AUTOSAR XML (schema 4-2-2)
package /MCU_FlatView/SwComponentTypes
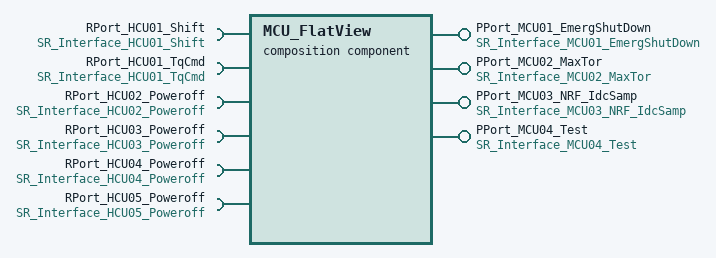
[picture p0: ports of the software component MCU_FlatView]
  composition sw component type MCU_FlatView
    provide port PPort_MCU01_EmergShutDown: provided-interface=SR_Interface_MCU01_EmergShutDown
    provide port PPort_MCU02_MaxTor: provided-interface=SR_Interface_MCU02_MaxTor
    provide port PPort_MCU03_NRF_IdcSamp: provided-interface=SR_Interface_MCU03_NRF_IdcSamp
    4 x require port:
      RPort_HCU01_Shift: nonqueued-receiver-com-spec{data-element=HCU01_Shift, alive-timeout=0.3}, required-interface=SR_Interface_HCU01_Shift
      RPort_HCU01_TqCmd: nonqueued-receiver-com-spec{data-element=HCU01_Tq_Cmd, alive-timeout=0.3}, required-interface=SR_Interface_HCU01_TqCmd
      RPort_HCU02_Poweroff: nonqueued-receiver-com-spec{data-element=HCU02_Poweroff, alive-timeout=0.3}, required-interface=SR_Interface_HCU02_Poweroff
      RPort_HCU03_Poweroff: nonqueued-receiver-com-spec{data-element=HCU03_Poweroff, alive-timeout=0.3}, required-interface=SR_Interface_HCU03_Poweroff
    provide port PPort_MCU04_Test: provided-interface=SR_Interface_MCU04_Test
    require port RPort_HCU04_Poweroff: nonqueued-receiver-com-spec{data-element=HCU04_Poweroff, alive-timeout=0.3}, required-interface=SR_Interface_HCU04_Poweroff
    require port RPort_HCU05_Poweroff: nonqueued-receiver-com-spec{data-element=HCU05_Poweroff, alive-timeout=0.3}, required-interface=SR_Interface_HCU05_Poweroff
    18 x component:
      CPT_ASW_BASE: type=ASW_BASE
      CPT_ASW_COM: type=ASW_COM
      CPT_ASW_CORE1: type=ASW_CORE1
      CPT_ASW_CORE2: type=ASW_CORE2
      CPT_ASW_NM: type=ASW_NM
      CPT_ASW_NVM: type=ASW_NVM
      CPT_ASW_WDG: type=ASW_WDG
      CPT_BswM: type=BswM
      CPT_ComM: type=ComM
      CPT_Dcm: type=Dcm
      CPT_Dem: type=Dem
      CPT_Dem_SWC: type=ASW_Dem
      CPT_Det: type=Det
      CPT_Diag: type=ASW_Diag
      CPT_EcuM: type=EcuM
      CPT_NvM: type=NvM
      CPT_Wdg: type=WdgM
      CPT_XCP: type=ASW_XCP
    connect CPT_ASW_BASE.PPort_SwcModeRequest -> CPT_BswM.RP_BswMArbitration_BswMSwcModeRequest
    connect CPT_ASW_NM.PP_BswMArbitration_BswM_MRP_Network -> CPT_BswM.RP_BswMArbitration_BswM_MRP_SWC_Network
    connect CPT_ASW_NM.PP_BswMArbitration_BswM_MRP_NmState -> CPT_BswM.RP_BswMArbitration_BswM_MRP_SWC_Network
    connect CPT_ComM.UM_ComMUser_Can_Network_Channel -> CPT_ASW_BASE.RPort_CurrentMode_CAN0
    connect CPT_ComM.UR_ComMUser_Can_Network_Channel -> CPT_ASW_NM.RP_ComM_UserRequest_CAN0
    connect CPT_ComM.modeLimitation -> CPT_ASW_NM.RPort_EcuModeLimitation
    connect CPT_Dcm.DCMServices -> CPT_Diag.RPort_DCMServices
    connect CPT_Dcm.P_DataServices_DcmDspData_SystemFaultRank -> CPT_Diag.RPort_DataServices_DcmDspData_SystemFaultRank_Write
    connect CPT_Dcm.P_DataServices_DcmDspData_VehicleSpeed -> CPT_Diag.RPort_DataServices_DcmDspData_VehicleSpeed_Write
    connect CPT_Dem.Event_DemEventParameter_C110117 -> CPT_Dem_SWC.Event_DemEventParameter_C110117
    connect CPT_Dem.Event_DemEventParameter_C110216 -> CPT_Dem_SWC.Event_DemEventParameter_C110216
    connect CPT_Dem.OpCycle_DemOperationCycle_0 -> CPT_Dem_SWC.RPort_OpCycle_DemOperationCycle_0
    connect CPT_Dem_SWC.PPort_CBReadData_DemDataElementClass_SystemFaultRank -> CPT_Dem.DataServices_DemDataElementClass_SystemFaultRank
    connect CPT_Dem_SWC.PPort_CBReadData_Dem_External_VehicleSpeed -> CPT_Dem.DataServices_DemDataElementClass_VehicleSpeed
    connect CPT_Dem_SWC.PPort_CBStatusComp_DemComponent_Busoff -> CPT_Dem.CBStatusComp_DemComponent_Busoff
    connect CPT_Dem_SWC.PPort_CBStatusComp_DemComponent_C110117 -> CPT_Dem.CBStatusComp_DemComponent_C110117
    connect CPT_Dem_SWC.PPort_CBStatusComp_DemComponent_C110216 -> CPT_Dem.CBStatusComp_DemComponent_C110216
    connect CPT_Dem_SWC.PPort_CBStatusComp_DemComponent_C153364 -> CPT_Dem.CBStatusComp_DemComponent_C153364
    connect CPT_Diag.PPort_IOControl_VacuumPumpPressure -> CPT_Dcm.DataServices_DcmDspData_VacuumPumpPressure_1100
    connect CPT_Diag.PPort_Routine_DriveVacuumPump -> CPT_Dcm.RoutineServices_DcmDspRoutine_DriveVacuumPump
    connect CPT_Diag.P_DataServices_DcmDspData_SystemFaultRank_Read -> CPT_Dcm.R_DataServices_DcmDspData_SystemFaultRank
    connect CPT_Diag.P_DataServices_DcmDspData_VehicleSpeed_Read -> CPT_Dcm.R_DataServices_DcmDspData_VehicleSpeed
    connect CPT_EcuM.bootTarget -> CPT_ASW_BASE.RPort_BootTarget
    connect CPT_EcuM.shutdownTarget -> CPT_ASW_BASE.RPort_SelectShutdownTarget
    connect CPT_NvM.NvM_NativeBlock_1024_1 -> CPT_ASW_NVM.RPort_ASW_NVM_BlockNative_1024_1
    connect CPT_NvM.NvM_NativeBlock_1024_2 -> CPT_ASW_NVM.RPort_ASW_NVM_BlockNative_1024_2
    connect CPT_Wdg.alive_WdgMSupervisedEntity_Alive_Supervision_Entity1 -> CPT_ASW_WDG.RPort_Alive_Supervision_Entity1
    connect CPT_Wdg.globalMode -> CPT_ASW_WDG.RPort_WdgM_GlobalMode
    connect CPT_Wdg.mode_WdgMSupervisedEntity_Alive_Supervision_Entity1 -> CPT_ASW_WDG.RPort_WdgM_InvidualMode_Alive_Supervision_Entity1
    delegate CPT_ASW_COM.PPort_MCU01_EmergShutDown <-> outer port PPort_MCU01_EmergShutDown
    delegate CPT_ASW_COM.PPort_MCU02_MaxTor <-> outer port PPort_MCU02_MaxTor
    delegate CPT_ASW_COM.PPort_MCU03_NRF_IdcSamp <-> outer port PPort_MCU03_NRF_IdcSamp
    delegate CPT_ASW_COM.RPort_HCU01_Shift <-> outer port RPort_HCU01_Shift
    delegate CPT_ASW_COM.RPort_HCU01_TqCmd <-> outer port RPort_HCU01_TqCmd
    delegate CPT_ASW_COM.RPort_HCU02_Poweroff <-> outer port RPort_HCU02_Poweroff
    delegate CPT_ASW_COM.RPott_HCU03_Poweroff <-> outer port RPort_HCU03_Poweroff
    delegate CPT_ASW_COM.PPort_MCU04_Test <-> outer port PPort_MCU04_Test
    delegate CPT_ASW_COM.RPort_HCU04_Poweroff <-> outer port RPort_HCU04_Poweroff
    delegate CPT_ASW_COM.RPort_HCU05_Poweroff <-> outer port RPort_HCU05_Poweroff
